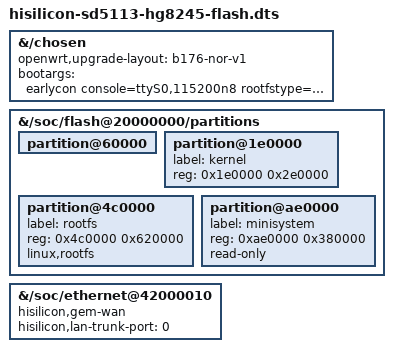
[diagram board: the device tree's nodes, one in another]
// SPDX-License-Identifier: GPL-2.0-only
#include "hisilicon-sd5113-hg8245-panel-wifi.dts"
#include "hisilicon-sd5113-hg8245-ar8316.dtsi"
#include "hisilicon-sd5113-hg8245-usb.dtsi"

&{/chosen} {
	openwrt,upgrade-layout = "b176-nor-v1";
	bootargs = "earlycon console=ttyS0,115200n8 rootfstype=squashfs ro";
};

&{/soc/flash@20000000/partitions} {
	/delete-node/ partition@1e0054;
	/delete-node/ partition@c16fdc;

	partition@60000 {
		/delete-property/ read-only;
	};
	partition@1e0000 {
		label = "kernel";
		reg = <0x1e0000 0x2e0000>;
	};
	partition@4c0000 {
		label = "rootfs";
		reg = <0x4c0000 0x620000>;
		linux,rootfs;
		/* OpenWrt derives rootfs_data from the end of SquashFS. */
	};
	partition@ae0000 {
		label = "minisystem";
		reg = <0xae0000 0x380000>;
		read-only;
	};
};

&{/soc/ethernet@42000010} {
	hisilicon,gem-wan;
	hisilicon,lan-trunk-port = <0>;
};
